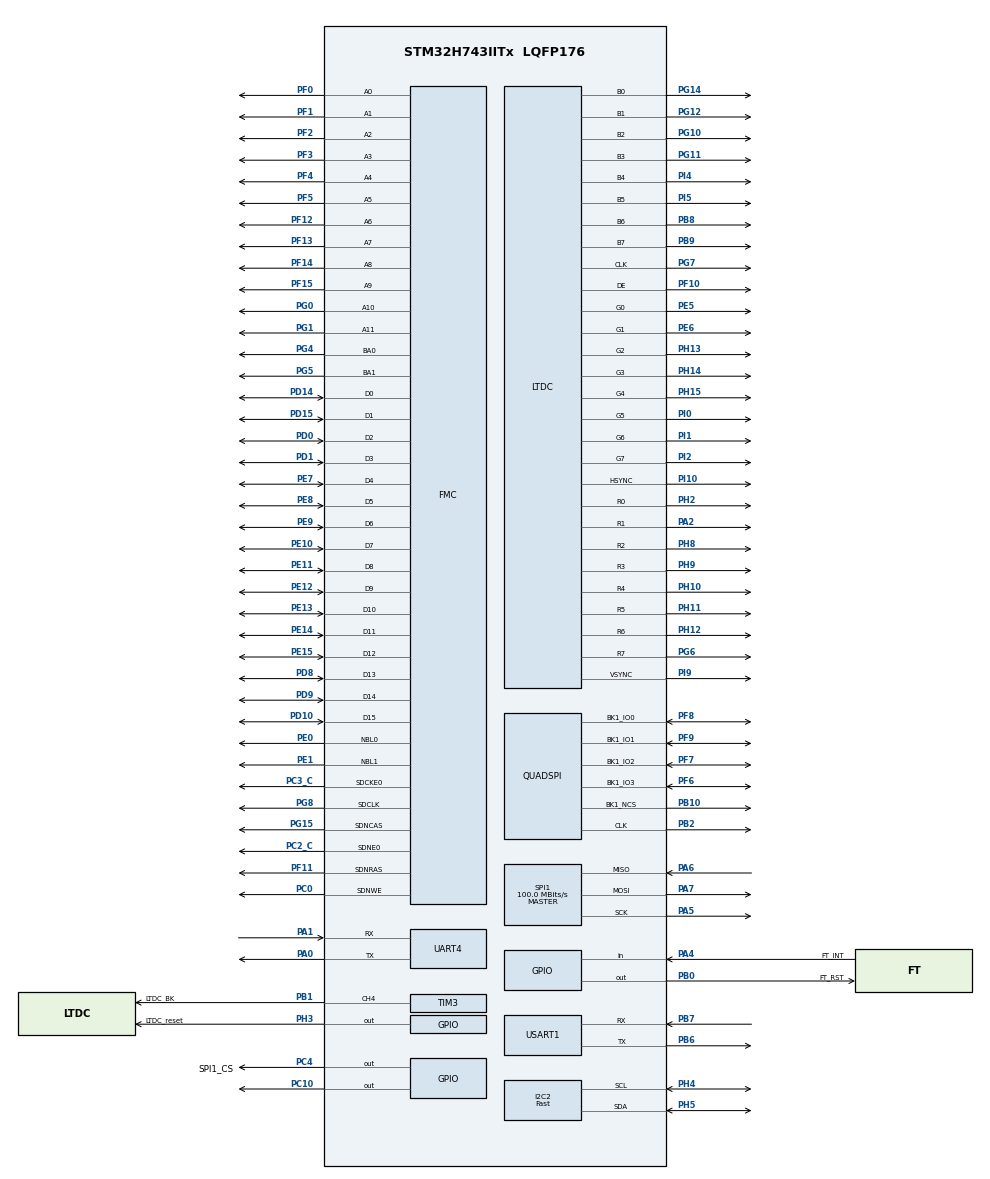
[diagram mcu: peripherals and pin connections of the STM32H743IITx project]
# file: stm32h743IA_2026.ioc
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CORTEX_M7.AccessPermission-Cortex_Memory_Protection_Unit_Region0_Settings=MPU_REGION_FULL_ACCESS
CORTEX_M7.BaseAddress-Cortex_Memory_Protection_Unit_Region0_Settings=0x90000000
CORTEX_M7.CPU_DCache=Enabled
CORTEX_M7.CPU_ICache=Enabled
CORTEX_M7.DisableExec-Cortex_Memory_Protection_Unit_Region0_Settings=MPU_INSTRUCTION_ACCESS_DISABLE
CORTEX_M7.Enable-Cortex_Memory_Protection_Unit_Region0_Settings=MPU_REGION_ENABLE
CORTEX_M7.IsBufferable-Cortex_Memory_Protection_Unit_Region0_Settings=MPU_ACCESS_BUFFERABLE
CORTEX_M7.IsCacheable-Cortex_Memory_Protection_Unit_Region0_Settings=MPU_ACCESS_CACHEABLE
CORTEX_M7.MPU_Control=MPU_PRIVILEGED_DEFAULT
CORTEX_M7.Size-Cortex_Memory_Protection_Unit_Region0_Settings=MPU_REGION_SIZE_32MB
CORTEX_M7.SubRegionDisable-Cortex_Memory_Protection_Unit_Region0_Settings=0
DMA2D.ColorMode=DMA2D_OUTPUT_RGB888
FMC.CASLatency1=FMC_SDRAM_CAS_LATENCY_2
FMC.ExitSelfRefreshDelay1=7
FMC.LoadToActiveDelay1=2
FMC.RCDDelay1=2
FMC.RPDelay1=2
FMC.ReadBurst1=FMC_SDRAM_RBURST_ENABLE
FMC.ReadPipeDelay1=FMC_SDRAM_RPIPE_DELAY_0
FMC.RowCycleDelay1=7
FMC.RowCycleDelay2=7
FMC.SDClockPeriod1=FMC_SDRAM_CLOCK_PERIOD_2
FMC.SelfRefreshTime1=4
FMC.WriteRecoveryTime1=3
I2C2.I2C_Speed_Mode=I2C_Fast
I2C2.Timing=0x009034B6
LTDC.ActiveH=PIXELS_H
LTDC.ActiveW=PIXELS_W
LTDC.Alpha_L0=255
LTDC.FBStartAdress_L0=0xc0000000
LTDC.HBP=140
LTDC.HFP=160
LTDC.HSync=20
LTDC.ImageHeight_L0=600
LTDC.ImageWidth_L0=1024
LTDC.Layers=0
LTDC.PixelFormat_L0=LTDC_PIXEL_FORMAT_RGB565
LTDC.VBP=20
LTDC.VFP=12
LTDC.VSync=3
LTDC.WindowX1_L0=PIXELS_W
LTDC.WindowY1_L0=PIXELS_H
Mcu.Family=STM32H7
Mcu.Name=STM32H743IITx
Mcu.Package=LQFP176
Mcu.UserConstants=PIXELS_DIR,1;PIXELS_H,600;PIXELS_W,1024;LTDC_BUFF_ADDR,0XC0000000
NVIC.DMA2D_IRQn=true\:0\:0\:false\:false\:true\:true\:true\:true
NVIC.PriorityGroup=NVIC_PRIORITYGROUP_4
PA0.Mode=Asynchronous
PA0.Signal=UART4_TX
PA1.Mode=Asynchronous
PA1.Signal=UART4_RX
PA13\ (JTMS/SWDIO).Mode=Serial_Wire
PA13\ (JTMS/SWDIO).PinAttribute=Free
PA13\ (JTMS/SWDIO).Signal=DEBUG_JTMS-SWDIO
PA14\ (JTCK/SWCLK).Mode=Serial_Wire
PA14\ (JTCK/SWCLK).Signal=DEBUG_JTCK-SWCLK
PA2.GPIO_Speed=GPIO_SPEED_FREQ_VERY_HIGH
PA2.Mode=RGB888
PA2.Signal=LTDC_R1
PA4.GPIO_Label=FT_INT
PA4.GPIO_PuPd=GPIO_PULLUP
PA4.Signal=GPIO_Input
PA5.Mode=Full_Duplex_Master
PA5.Signal=SPI1_SCK
PA6.Mode=Full_Duplex_Master
PA6.Signal=SPI1_MISO
PA7.Mode=Full_Duplex_Master
PA7.Signal=SPI1_MOSI
PB0.GPIO_Label=FT_RST
PB0.GPIO_PuPd=GPIO_NOPULL
PB0.Signal=GPIO_Output
PB1.GPIO_Label=LTDC_BK
PB1.Signal=S_TIM3_CH4
PB10.GPIO_Speed=GPIO_SPEED_FREQ_VERY_HIGH
PB10.Mode=Single Bank 1
PB10.Signal=QUADSPI_BK1_NCS
PB2.GPIO_Speed=GPIO_SPEED_FREQ_VERY_HIGH
PB2.Mode=Single Bank 1
PB2.Signal=QUADSPI_CLK
PB6.Mode=Asynchronous
PB6.Signal=USART1_TX
PB7.Mode=Asynchronous
PB7.Signal=USART1_RX
PB8.GPIO_FM8=__NULL
PB8.GPIO_Speed=GPIO_SPEED_FREQ_VERY_HIGH
PB8.Mode=RGB888
PB8.PinAttribute=Free
PB8.Signal=LTDC_B6
PB9.GPIO_Speed=GPIO_SPEED_FREQ_VERY_HIGH
PB9.Mode=RGB888
PB9.Signal=LTDC_B7
PC0.Signal=FMC_SDNWE
PC10.Signal=GPIO_Output
PC14-OSC32_IN\ (OSC32_IN).Mode=LSE-External-Clock-Source
PC14-OSC32_IN\ (OSC32_IN).PinAttribute=Free
PC14-OSC32_IN\ (OSC32_IN).Signal=RCC_OSC32_IN
PC2_C.Mode=SdramChipSelect1_1
PC2_C.Signal=FMC_SDNE0
PC3_C.Mode=SdramChipSelect1_1
PC3_C.Signal=FMC_SDCKE0
PC4.GPIO_Label=SPI1_CS
PC4.Signal=GPIO_Output
PD0.Signal=FMC_D2_DA2
PD1.Signal=FMC_D3_DA3
PD10.PinAttribute=Free
PD10.Signal=FMC_D15_DA15
PD14.PinAttribute=Free
PD14.Signal=FMC_D0_DA0
PD15.Signal=FMC_D1_DA1
PD8.PinAttribute=Free
PD8.Signal=FMC_D13_DA13
PD9.PinAttribute=Free
PD9.Signal=FMC_D14_DA14
PE0.Signal=FMC_NBL0
PE1.Signal=FMC_NBL1
PE10.Signal=FMC_D7_DA7
PE11.Signal=FMC_D8_DA8
PE12.Signal=FMC_D9_DA9
PE13.Signal=FMC_D10_DA10
PE14.Signal=FMC_D11_DA11
PE15.Signal=FMC_D12_DA12
PE5.GPIO_Speed=GPIO_SPEED_FREQ_VERY_HIGH
PE5.Mode=RGB888
PE5.PinAttribute=Free
PE5.Signal=LTDC_G0
PE6.GPIO_Speed=GPIO_SPEED_FREQ_VERY_HIGH
PE6.Mode=RGB888
PE6.PinAttribute=Free
PE6.Signal=LTDC_G1
PE7.Signal=FMC_D4_DA4
PE8.Signal=FMC_D5_DA5
PE9.Signal=FMC_D6_DA6
PF0.PinAttribute=Free
PF0.Signal=FMC_A0
PF1.Signal=FMC_A1
PF10.GPIO_Speed=GPIO_SPEED_FREQ_VERY_HIGH
PF10.Mode=RGB888
PF10.PinAttribute=Free
PF10.Signal=LTDC_DE
PF11.Signal=FMC_SDNRAS
PF12.Signal=FMC_A6
PF13.Signal=FMC_A7
PF14.Signal=FMC_A8
PF15.Signal=FMC_A9
PF2.Signal=FMC_A2
PF3.Signal=FMC_A3
PF4.Signal=FMC_A4
PF5.Signal=FMC_A5
PF6.GPIO_Speed=GPIO_SPEED_FREQ_VERY_HIGH
PF6.Mode=Single Bank 1
PF6.PinAttribute=Free
PF6.Signal=QUADSPI_BK1_IO3
PF7.GPIO_Speed=GPIO_SPEED_FREQ_VERY_HIGH
PF7.Mode=Single Bank 1
PF7.PinAttribute=Free
PF7.Signal=QUADSPI_BK1_IO2
PF8.GPIO_Speed=GPIO_SPEED_FREQ_VERY_HIGH
PF8.Mode=Single Bank 1
PF8.PinAttribute=Free
PF8.Signal=QUADSPI_BK1_IO0
PF9.GPIO_Speed=GPIO_SPEED_FREQ_VERY_HIGH
PF9.Mode=Single Bank 1
PF9.PinAttribute=Free
PF9.Signal=QUADSPI_BK1_IO1
PG0.Signal=FMC_A10
PG1.Signal=FMC_A11
PG10.GPIO_Speed=GPIO_SPEED_FREQ_VERY_HIGH
PG10.Mode=RGB888
PG10.Signal=LTDC_B2
PG11.GPIO_Speed=GPIO_SPEED_FREQ_VERY_HIGH
PG11.Mode=RGB888
PG11.Signal=LTDC_B3
PG12.GPIO_Speed=GPIO_SPEED_FREQ_VERY_HIGH
PG12.Mode=RGB888
PG12.Signal=LTDC_B1
PG14.GPIO_Speed=GPIO_SPEED_FREQ_VERY_HIGH
PG14.Mode=RGB888
PG14.Signal=LTDC_B0
PG15.Signal=FMC_SDNCAS
PG4.Signal=FMC_A14_BA0
PG5.Signal=FMC_A15_BA1
PG6.GPIO_Speed=GPIO_SPEED_FREQ_VERY_HIGH
PG6.Mode=RGB888
PG6.Signal=LTDC_R7
PG7.GPIO_Speed=GPIO_SPEED_FREQ_VERY_HIGH
PG7.Mode=RGB888
PG7.PinAttribute=Free
PG7.Signal=LTDC_CLK
PG8.PinAttribute=Free
PG8.Signal=FMC_SDCLK
PH0-OSC_IN\ (PH0).Mode=HSE-External-Clock-Source
PH0-OSC_IN\ (PH0).PinAttribute=Free
PH0-OSC_IN\ (PH0).Signal=RCC_OSC_IN
PH10.GPIO_Speed=GPIO_SPEED_FREQ_VERY_HIGH
PH10.Mode=RGB888
PH10.Signal=LTDC_R4
PH11.GPIO_Speed=GPIO_SPEED_FREQ_VERY_HIGH
PH11.Mode=RGB888
PH11.Signal=LTDC_R5
PH12.GPIO_Speed=GPIO_SPEED_FREQ_VERY_HIGH
PH12.Mode=RGB888
PH12.PinAttribute=Free
PH12.Signal=LTDC_R6
PH13.GPIO_Speed=GPIO_SPEED_FREQ_VERY_HIGH
PH13.Mode=RGB888
PH13.PinAttribute=Free
PH13.Signal=LTDC_G2
PH14.GPIO_Speed=GPIO_SPEED_FREQ_VERY_HIGH
PH14.Mode=RGB888
PH14.PinAttribute=Free
PH14.Signal=LTDC_G3
PH15.GPIO_Speed=GPIO_SPEED_FREQ_VERY_HIGH
PH15.Mode=RGB888
PH15.Signal=LTDC_G4
PH2.GPIO_Speed=GPIO_SPEED_FREQ_VERY_HIGH
PH2.Mode=RGB888
PH2.Signal=LTDC_R0
PH3.GPIO_Label=LTDC_reset
PH3.Signal=GPIO_Output
PH4.Mode=I2C
PH4.Signal=I2C2_SCL
PH5.Mode=I2C
PH5.Signal=I2C2_SDA
PH8.GPIO_Speed=GPIO_SPEED_FREQ_VERY_HIGH
PH8.Mode=RGB888
PH8.Signal=LTDC_R2
PH9.GPIO_Speed=GPIO_SPEED_FREQ_VERY_HIGH
PH9.Mode=RGB888
PH9.Signal=LTDC_R3
PI0.GPIO_Speed=GPIO_SPEED_FREQ_VERY_HIGH
PI0.Mode=RGB888
PI0.Signal=LTDC_G5
PI1.GPIO_Speed=GPIO_SPEED_FREQ_VERY_HIGH
PI1.Mode=RGB888
PI1.Signal=LTDC_G6
PI10.GPIO_Speed=GPIO_SPEED_FREQ_VERY_HIGH
PI10.Mode=RGB888
PI10.PinAttribute=Free
PI10.Signal=LTDC_HSYNC
PI2.GPIO_Speed=GPIO_SPEED_FREQ_VERY_HIGH
PI2.Mode=RGB888
PI2.Signal=LTDC_G7
PI4.GPIO_Speed=GPIO_SPEED_FREQ_VERY_HIGH
PI4.Mode=RGB888
PI4.Signal=LTDC_B4
PI5.GPIO_Speed=GPIO_SPEED_FREQ_VERY_HIGH
PI5.Mode=RGB888
PI5.Signal=LTDC_B5
PI9.GPIO_Speed=GPIO_SPEED_FREQ_VERY_HIGH
PI9.Mode=RGB888
PI9.PinAttribute=Free
PI9.Signal=LTDC_VSYNC
ProjectManager.HeapSize=0x200
ProjectManager.StackSize=0x400
ProjectManager.TargetToolchain=STM32CubeIDE
QUADSPI.ChipSelectHighTime=QSPI_CS_HIGH_TIME_1_CYCLE
QUADSPI.ClockPrescaler=1
QUADSPI.DeviceType=SPI_DEVICE_FLASH
QUADSPI.FifoThreshold=4
QUADSPI.FlashSize=24
QUADSPI.SampleShifting=QSPI_SAMPLE_SHIFTING_HALFCYCLE
RCC.ADCFreq_Value=129000000
RCC.APB1Freq_Value=100000000
RCC.APB2Freq_Value=100000000
RCC.APB3Freq_Value=100000000
RCC.APB4Freq_Value=100000000
RCC.CortexFreq_Value=400000000
RCC.D1PPRE=RCC_APB3_DIV2
RCC.D2PPRE1=RCC_APB1_DIV2
RCC.D2PPRE2=RCC_APB2_DIV2
RCC.D3PPRE=RCC_APB4_DIV2
RCC.DIVM1=4
RCC.DIVM3=1
RCC.DIVN1=50
RCC.DIVN3=4
RCC.DIVQ1=4
RCC.DIVR3=5
RCC.HCLKFreq_Value=200000000
RCC.HPRE=RCC_HCLK_DIV2
RCC.PLL2FRACN=0
RCC.PLL2_VCI_Range-AdvancedSettings=RCC_PLL2VCIRANGE_3
RCC.PLL3FRACN=0
RCC.PLLFRACN=0
RCC.SYSCLKFreq_VALUE=400000000
RCC.SYSCLKSource=RCC_SYSCLKSOURCE_PLLCLK
RCC.USBFreq_Value=200000000
SH.FMC_A0.0=FMC_A0,12b-sda1
SH.FMC_A1.0=FMC_A1,12b-sda1
SH.FMC_A10.0=FMC_A10,12b-sda1
SH.FMC_A11.0=FMC_A11,12b-sda1
SH.FMC_A14_BA0.0=FMC_BA0,FourSdramBanks1
SH.FMC_A15_BA1.0=FMC_BA1,FourSdramBanks1
SH.FMC_A2.0=FMC_A2,12b-sda1
SH.FMC_A3.0=FMC_A3,12b-sda1
SH.FMC_A4.0=FMC_A4,12b-sda1
SH.FMC_A5.0=FMC_A5,12b-sda1
SH.FMC_A6.0=FMC_A6,12b-sda1
SH.FMC_A7.0=FMC_A7,12b-sda1
SH.FMC_A8.0=FMC_A8,12b-sda1
SH.FMC_A9.0=FMC_A9,12b-sda1
SH.FMC_D0_DA0.0=FMC_D0,sd-16b-d1
SH.FMC_D10_DA10.0=FMC_D10,sd-16b-d1
SH.FMC_D11_DA11.0=FMC_D11,sd-16b-d1
SH.FMC_D12_DA12.0=FMC_D12,sd-16b-d1
SH.FMC_D13_DA13.0=FMC_D13,sd-16b-d1
SH.FMC_D14_DA14.0=FMC_D14,sd-16b-d1
SH.FMC_D15_DA15.0=FMC_D15,sd-16b-d1
SH.FMC_D1_DA1.0=FMC_D1,sd-16b-d1
SH.FMC_D2_DA2.0=FMC_D2,sd-16b-d1
SH.FMC_D3_DA3.0=FMC_D3,sd-16b-d1
SH.FMC_D4_DA4.0=FMC_D4,sd-16b-d1
SH.FMC_D5_DA5.0=FMC_D5,sd-16b-d1
SH.FMC_D6_DA6.0=FMC_D6,sd-16b-d1
SH.FMC_D7_DA7.0=FMC_D7,sd-16b-d1
SH.FMC_D8_DA8.0=FMC_D8,sd-16b-d1
SH.FMC_D9_DA9.0=FMC_D9,sd-16b-d1
SH.FMC_NBL0.0=FMC_NBL0,Sd2ByteEnable1
SH.FMC_NBL1.0=FMC_NBL1,Sd2ByteEnable1
SH.FMC_SDCLK.0=FMC_SDCLK,12b-sda1
SH.FMC_SDNCAS.0=FMC_SDNCAS,12b-sda1
SH.FMC_SDNRAS.0=FMC_SDNRAS,12b-sda1
SH.FMC_SDNWE.0=FMC_SDNWE,12b-sda1
SH.S_TIM3_CH4.0=TIM3_CH4,PWM Generation4 CH4
SPI1.CalculateBaudRate=100.0 MBits/s
SPI1.Direction=SPI_DIRECTION_2LINES
SPI1.Mode=SPI_MODE_MASTER
SPI1.VirtualType=VM_MASTER
TIM3.Channel-PWM\ Generation4\ CH4=TIM_CHANNEL_4
TIM3.OCFastMode_PWM-PWM\ Generation4\ CH4=TIM_OCFAST_ENABLE
TIM3.Period=10000
TIM3.Prescaler=100-1
UART4.SwapParam=UART_ADVFEATURE_SWAP_DISABLE
USART1.DMADisableonRxErrorParam=ADVFEATURE_DMA_DISABLEONRXERROR
USART1.VirtualMode-Asynchronous=VM_ASYNC
VP_DMA2D_VS_DMA2D.Mode=DMA2D_Activate
VP_MEMORYMAP_VS_MEMORYMAP.Mode=CurAppReg
VP_TIM3_VS_ClockSourceINT.Mode=Internal
board=custom

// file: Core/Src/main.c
/* USER CODE BEGIN Header */
/**
  ******************************************************************************
  * @file           : main.c
  * @brief          : Main program body
  ******************************************************************************
  * @attention
  *
  * Copyright (c) 2025 STMicroelectronics.
  * All rights reserved.
  *
  * This software is licensed under terms that can be found in the LICENSE file
  * in the root directory of this software component.
  * If no LICENSE file comes with this software, it is provided AS-IS.
  *

  */
// I2C ADRESSS 0X38
/* USER CODE END Header */
#include "main.h"
#include "dma2d.h"
#include "i2c.h"
#include "ltdc.h"
#include "memorymap.h"
#include "quadspi.h"
#include "spi.h"
#include "tim.h"
#include "usart.h"
#include "gpio.h"
#include "fmc.h"

/* USER CODE BEGIN Includes */
#include "string.h"

//#include "w9825g6kh.h"
#include <stdio.h>
//#include "image.h"
//#include <ft5426.h>
#include <touch.h>
//#include <ctpiic.h>
//#include <ctpiic.h>
//#include <font.h>

/* USER CODE END Includes */

/* USER CODE BEGIN PV */
uint8_t tx_buffer[27]="welcom to bynaryupdate\n";
uint32_t ID=0;
uint16_t  IDM=0;
uint8_t Buffer[25] = {0};
uint8_t Space[] = " - ";
uint8_t StartMSG[] = "Starting I2C Scanning: \r\n";
uint8_t EndMSG[] = "Done! \r\n\r\n";
char wdata[]="hello wArld";
char rdata[11];
uint8_t writebuf[]= "hello word from Qspi marche RR";
uint8_t Readbuf[30];
/* USER CODE END PV */

void SystemClock_Config(void);
static void MPU_Config(void);

/* USER CODE BEGIN 0 */
//#define SDRAM_ADD 0xC0000000

#ifdef __GNUC__

#define PUTCHAR_PROTOTYPE int __io_putchar(int ch)
#define GETCHAR_PROTOTYPE int __io_getchar(void)
#else
#define PUTCHAR_PROTOTYPE int fputc(int ch, FILE *f)
#define GETCHAR_PROTOTYPE int fgetc( FILE *f)
#endif /* __GNUC__ */

PUTCHAR_PROTOTYPE{
	  HAL_UART_Transmit(&huart1,(uint8_t *)&ch,1 , HAL_MAX_DELAY);
	return ch;
}

GETCHAR_PROTOTYPE{
	uint8_t ch =0;
	__HAL_UART_CLEAR_OREFLAG(&huart1);
	HAL_UART_Receive(&huart1,(uint8_t *)&ch , 1, HAL_MAX_DELAY);
	HAL_UART_Transmit(&huart1,(uint8_t *)&ch , 1, HAL_MAX_DELAY);
	return ch;
}

/* USER CODE END 0 */

int main(void)
{

  /* MPU Configuration--------------------------------------------------------*/
  MPU_Config();

  /* Enable the CPU Cache */

  /* Enable I-Cache---------------------------------------------------------*/
  SCB_EnableICache();

  /* Enable D-Cache---------------------------------------------------------*/
  SCB_EnableDCache();

  /* MCU Configuration--------------------------------------------------------*/

  /* Reset of all peripherals, Initializes the Flash interface and the Systick. */
  HAL_Init();

  /* Configure the system clock */
  SystemClock_Config();

  /* Initialize all configured peripherals */
  MX_GPIO_Init();
  MX_LTDC_Init();
  MX_QUADSPI_Init();
  MX_FMC_Init();
  MX_I2C2_Init();
  MX_SPI1_Init();
  MX_UART4_Init();
  MX_USART1_UART_Init();
  MX_TIM3_Init();
  MX_DMA2D_Init();
  /* USER CODE BEGIN 2 */

  Backlight();

SDRAM_InitSequence();

 FT5426_Init();

LTDC_Init();
LTDC_Clear(BLACK);
	  	 HAL_Delay(500);
	  		  	  LTDC_Fill(0,0,1020,600,BLUE);
  /* USER CODE END 2 */

  /* Infinite loop */
  /* USER CODE BEGIN WHILE */
  while (1)
  {
		  	FT5426_Scan();
    /* USER CODE END WHILE */

  }
}

void SystemClock_Config(void)
{
  RCC_OscInitTypeDef RCC_OscInitStruct = {0};
  RCC_ClkInitTypeDef RCC_ClkInitStruct = {0};

  /** Supply configuration update enable
  */
  HAL_PWREx_ConfigSupply(PWR_LDO_SUPPLY);

  /** Configure the main internal regulator output voltage
  */
  __HAL_PWR_VOLTAGESCALING_CONFIG(PWR_REGULATOR_VOLTAGE_SCALE1);

  while(!__HAL_PWR_GET_FLAG(PWR_FLAG_VOSRDY)) {}

  /** Initializes the RCC Oscillators according to the specified parameters
  * in the RCC_OscInitTypeDef structure.
  */
  RCC_OscInitStruct.OscillatorType = RCC_OSCILLATORTYPE_HSI;
  RCC_OscInitStruct.HSIState = RCC_HSI_DIV1;
  RCC_OscInitStruct.HSICalibrationValue = RCC_HSICALIBRATION_DEFAULT;
  RCC_OscInitStruct.PLL.PLLState = RCC_PLL_ON;
  RCC_OscInitStruct.PLL.PLLSource = RCC_PLLSOURCE_HSI;
  RCC_OscInitStruct.PLL.PLLM = 4;
  RCC_OscInitStruct.PLL.PLLN = 50;
  RCC_OscInitStruct.PLL.PLLP = 2;
  RCC_OscInitStruct.PLL.PLLQ = 4;
  RCC_OscInitStruct.PLL.PLLR = 2;
  RCC_OscInitStruct.PLL.PLLRGE = RCC_PLL1VCIRANGE_3;
  RCC_OscInitStruct.PLL.PLLVCOSEL = RCC_PLL1VCOWIDE;
  RCC_OscInitStruct.PLL.PLLFRACN = 0;
  if (HAL_RCC_OscConfig(&RCC_OscInitStruct) != HAL_OK)
  {
    Error_Handler();
  }

  /** Initializes the CPU, AHB and APB buses clocks
  */
  RCC_ClkInitStruct.ClockType = RCC_CLOCKTYPE_HCLK|RCC_CLOCKTYPE_SYSCLK
                              |RCC_CLOCKTYPE_PCLK1|RCC_CLOCKTYPE_PCLK2
                              |RCC_CLOCKTYPE_D3PCLK1|RCC_CLOCKTYPE_D1PCLK1;
  RCC_ClkInitStruct.SYSCLKSource = RCC_SYSCLKSOURCE_PLLCLK;
  RCC_ClkInitStruct.SYSCLKDivider = RCC_SYSCLK_DIV1;
  RCC_ClkInitStruct.AHBCLKDivider = RCC_HCLK_DIV2;
  RCC_ClkInitStruct.APB3CLKDivider = RCC_APB3_DIV2;
  RCC_ClkInitStruct.APB1CLKDivider = RCC_APB1_DIV2;
  RCC_ClkInitStruct.APB2CLKDivider = RCC_APB2_DIV2;
  RCC_ClkInitStruct.APB4CLKDivider = RCC_APB4_DIV2;

  if (HAL_RCC_ClockConfig(&RCC_ClkInitStruct, FLASH_LATENCY_2) != HAL_OK)
  {
    Error_Handler();
  }
}

 /* MPU Configuration */

void MPU_Config(void)
{
  MPU_Region_InitTypeDef MPU_InitStruct = {0};

  /* Disables the MPU */
  HAL_MPU_Disable();

  /** Initializes and configures the Region and the memory to be protected
  */
  MPU_InitStruct.Enable = MPU_REGION_ENABLE;
  MPU_InitStruct.Number = MPU_REGION_NUMBER0;
  MPU_InitStruct.BaseAddress = 0x90000000;
  MPU_InitStruct.Size = MPU_REGION_SIZE_32MB;
  MPU_InitStruct.SubRegionDisable = 0;
  MPU_InitStruct.TypeExtField = MPU_TEX_LEVEL0;
  MPU_InitStruct.AccessPermission = MPU_REGION_FULL_ACCESS;
  MPU_InitStruct.DisableExec = MPU_INSTRUCTION_ACCESS_DISABLE;
  MPU_InitStruct.IsShareable = MPU_ACCESS_NOT_SHAREABLE;
  MPU_InitStruct.IsCacheable = MPU_ACCESS_CACHEABLE;
  MPU_InitStruct.IsBufferable = MPU_ACCESS_BUFFERABLE;

  HAL_MPU_ConfigRegion(&MPU_InitStruct);
  /* Enables the MPU */
  HAL_MPU_Enable(MPU_PRIVILEGED_DEFAULT);

}

void Error_Handler(void)
{
  __disable_irq();
  while (1)
  {
  }
}
